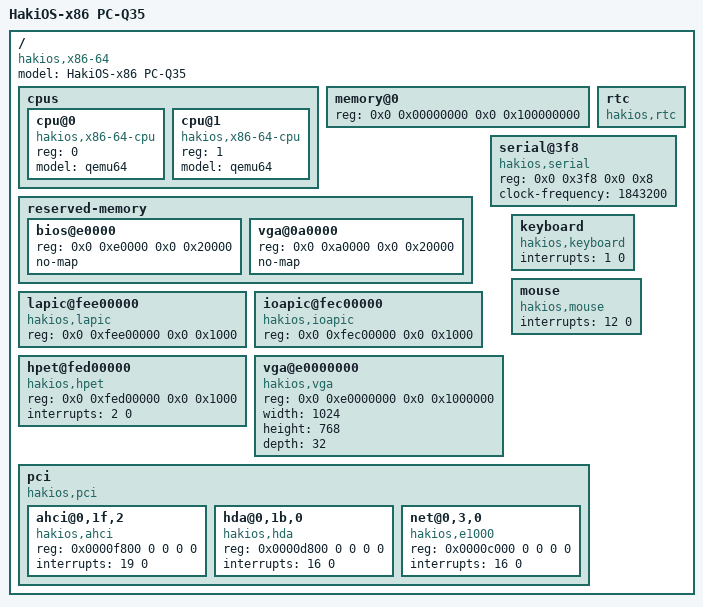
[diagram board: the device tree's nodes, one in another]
/dts-v1/;

/ {
    #address-cells = <2>;
    #size-cells = <2>;
    model = "HakiOS-x86 PC-Q35";
    compatible = "hakios,x86-64\0hakios,pc-q35";

    cpus {
        #address-cells = <1>;
        #size-cells = <0>;

        cpu@0 {
            device_type = "cpu";
            reg = <0>;
            model = "qemu64";
            compatible = "hakios,x86-64-cpu";
        };

        cpu@1 {
            device_type = "cpu";
            reg = <1>;
            model = "qemu64";
            compatible = "hakios,x86-64-cpu";
        };
    };

    memory@0 {
        device_type = "memory";
        reg = <0x0 0x00000000 0x0 0x100000000>; /* 4GB */
    };

    reserved-memory {
        #address-cells = <2>;
        #size-cells = <2>;
        ranges;

        bios@e0000 {
            reg = <0x0 0xe0000 0x0 0x20000>;
            no-map;
        };

        vga@0a0000 {
            reg = <0x0 0xa0000 0x0 0x20000>;
            no-map;
        };
    };

    lapic@fee00000 {
        compatible = "hakios,lapic\0hakios,apic";
        reg = <0x0 0xfee00000 0x0 0x1000>;
    };

    ioapic@fec00000 {
        compatible = "hakios,ioapic\0hakios,apic";
        reg = <0x0 0xfec00000 0x0 0x1000>;
    };

    hpet@fed00000 {
        compatible = "hakios,hpet";
        reg = <0x0 0xfed00000 0x0 0x1000>;
        interrupts = <2 0>;
    };

    rtc {
        compatible = "hakios,rtc\0motorola,mc146818";
    };

    serial@3f8 {
        compatible = "hakios,serial\0ns16550a";
        reg = <0x0 0x3f8 0x0 0x8>;
        clock-frequency = <1843200>;
    };

    vga@e0000000 {
        compatible = "hakios,vga\0bochs,vbe";
        reg = <0x0 0xe0000000 0x0 0x1000000>;
        width = <1024>;
        height = <768>;
        depth = <32>;
    };

    keyboard {
        compatible = "hakios,keyboard\0intel,i8042";
        interrupts = <1 0>;
    };

    mouse {
        compatible = "hakios,mouse\0intel,i8042";
        interrupts = <12 0>;
    };

    pci {
        compatible = "hakios,pci\0intel,q35-pci";
        #address-cells = <3>;
        #size-cells = <2>;

        ahci@0,1f,2 {
            compatible = "hakios,ahci\0intel,ich9-ahci";
            reg = <0x0000f800 0 0 0 0>;
            interrupts = <19 0>;
        };

        hda@0,1b,0 {
            compatible = "hakios,hda\0intel,hda";
            reg = <0x0000d800 0 0 0 0>;
            interrupts = <16 0>;
        };

        net@0,3,0 {
            compatible = "hakios,e1000\0intel,82540em";
            reg = <0x0000c000 0 0 0 0>;
            interrupts = <16 0>;
        };
    };
};
